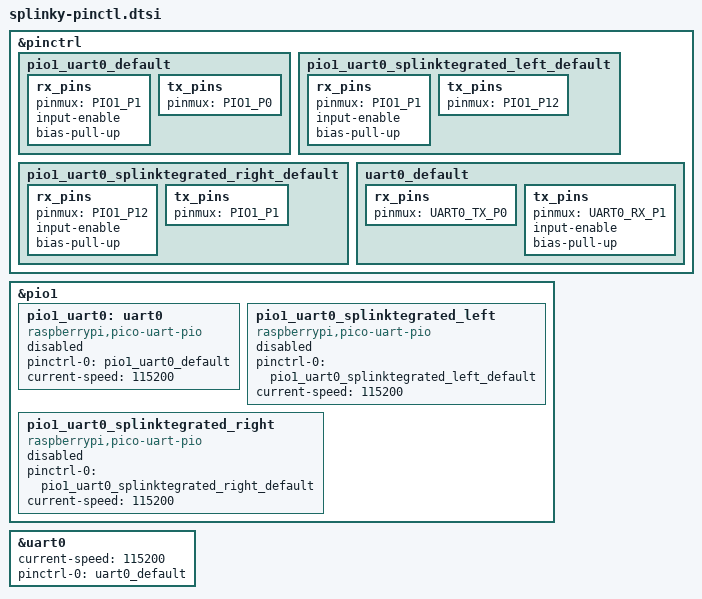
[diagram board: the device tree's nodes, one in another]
/*
 * Copyright (c) 2021, Yonatan Schachter
 * SPDX-License-Identifier: Apache-2.0
 */

#include <dt-bindings/pinctrl/rpi-pico-rp2040-pinctrl.h>

&pinctrl {
    pio1_uart0_default: pio1_uart0_default {
		rx_pins {
			pinmux = <PIO1_P1>;
			input-enable;
			bias-pull-up;
		};
		tx_pins {
			pinmux = <PIO1_P0>;
		};
    };

    pio1_uart0_splinktegrated_left_default: pio1_uart0_splinktegrated_left_default {
		rx_pins {
			pinmux = <PIO1_P1>;
			input-enable;
			bias-pull-up;
		};
		tx_pins {
			pinmux = <PIO1_P12>;
		};
    };
    pio1_uart0_splinktegrated_right_default: pio1_uart0_splinktegrated_right_default {
		rx_pins {
			pinmux = <PIO1_P12>;
			input-enable;
			bias-pull-up;
		};
		tx_pins {
			pinmux = <PIO1_P1>;
		};
    };

    uart0_default: uart0_default {
        rx_pins {
            pinmux = <UART0_TX_P0>;
        };
        tx_pins {
            pinmux = <UART0_RX_P1>;
			input-enable;
			bias-pull-up;
        };
	};
};

&pio1 {
 	status = "okay";

	pio1_uart0: uart0 {
		pinctrl-0 = <&pio1_uart0_default>;
		pinctrl-names = "default";

		compatible = "raspberrypi,pico-uart-pio";
		current-speed = <115200>;
		status = "disabled";
	};

	pio1_uart0_splinktegrated_left: pio1_uart0_splinktegrated_left {
		pinctrl-0 = <&pio1_uart0_splinktegrated_left_default>;
		pinctrl-names = "default";

		compatible = "raspberrypi,pico-uart-pio";
		current-speed = <115200>;
		status = "disabled";
	};
	pio1_uart0_splinktegrated_right: pio1_uart0_splinktegrated_right {
		pinctrl-0 = <&pio1_uart0_splinktegrated_right_default>;
		pinctrl-names = "default";

		compatible = "raspberrypi,pico-uart-pio";
		current-speed = <115200>;
		status = "disabled";
	};
};

&uart0 {
    status = "okay";
    current-speed = <115200>;
    pinctrl-0 = <&uart0_default>;
    // pinctrl-names = "default", "sleep";
    pinctrl-names = "default";
};
